# APM32F070 register map
File version: 1.0
Registers are 32-bit, read-write, reset 0x0 unless marked. A register's access mark holds for its fields unless they carry their own. Offsets are from the block's base; [hi:lo] are bit positions; {n}, {i} and the like mark numbered series.

## SYSCFG — System configuration controller
Base 0x40010000
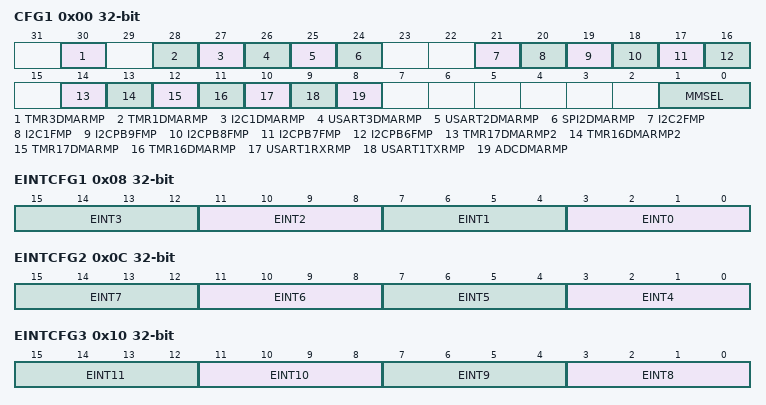
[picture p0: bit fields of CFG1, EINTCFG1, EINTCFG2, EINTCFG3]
0x00 CFG1 — configuration register 1
  [30] TMR3DMARMP — TMR3 DMA request remapping bit
  [28] TMR1DMARMP — TMR1 DMA request remapping bit
  [27] I2C1DMARMP — I2C1 DMA request remapping bit
  [26] USART3DMARMP — USART3 DMA request remapping bit
  [25] USART2DMARMP — USART2 DMA request remapping bit
  [24] SPI2DMARMP — SPI2 DMA request remapping bit.
  [21] I2C2FMP — FM+ driving capability activation for I2C1
  [20] I2C1FMP — FM+ driving capability activation for I2C1
  [19] I2CPB9FMP — Fast Mode Plus (FM+) driving capability activation bits.
  [18] I2CPB8FMP — Fast Mode Plus (FM+) driving capability activation bits.
  [17] I2CPB7FMP — Fast Mode Plus (FM+) driving capability activation bits.
  [16] I2CPB6FMP — Fast Mode Plus (FM plus) driving capability activation bits.
  [14] TMR17DMARMP2 — TMR17 alternate DMA request remapping bit.
  [13] TMR16DMARMP2 — TMR16 alternate DMA request remapping bit.
  [12] TMR17DMARMP — TMR17 DMA request remapping bit
  [11] TMR16DMARMP — TMR16 DMA request remapping bit
  [10] USART1RXRMP — USART1_RX DMA request remapping bit
  [9] USART1TXRMP — USART1_TX DMA remapping bit
  [8] ADCDMARMP — ADC DMA remapping bit
  [1:0] MMSEL — Memory mapping selection bits
0x08 EINTCFG1 — external interrupt configuration register 1
  [4n+3:4n] EINT{n} (n=0..3) — EINT {n} configuration bits
0x0C EINTCFG2 — external interrupt configuration register 2
  [4n-13:4n-16] EINT{n} (n=4..7) — EINT {n} configuration bits
0x10 EINTCFG3 — external interrupt configuration register 3
  [4n-29:4n-32] EINT{n} (n=8..11) — EINT {n} configuration bits
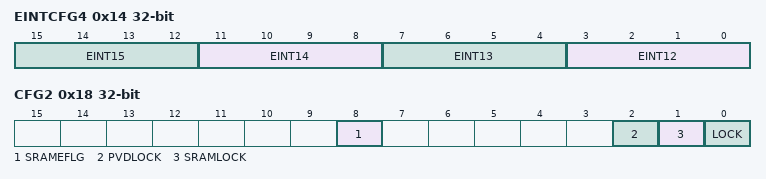
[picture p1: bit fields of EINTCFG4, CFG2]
0x14 EINTCFG4 — external interrupt configuration register 4
  [4n-45:4n-48] EINT{n} (n=12..15) — EINT {n} configuration bits
0x18 CFG2 — configuration register 2
  [8] SRAMEFLG — SRAM parity error flag
  [2] PVDLOCK — PVD lock enable bit
  [1] SRAMLOCK — SRAM parity lock bit
  [0] LOCK — Cortex-M0 Hardfault enable bit

## ADC — Analog-to-digital converter
Base 0x40012400
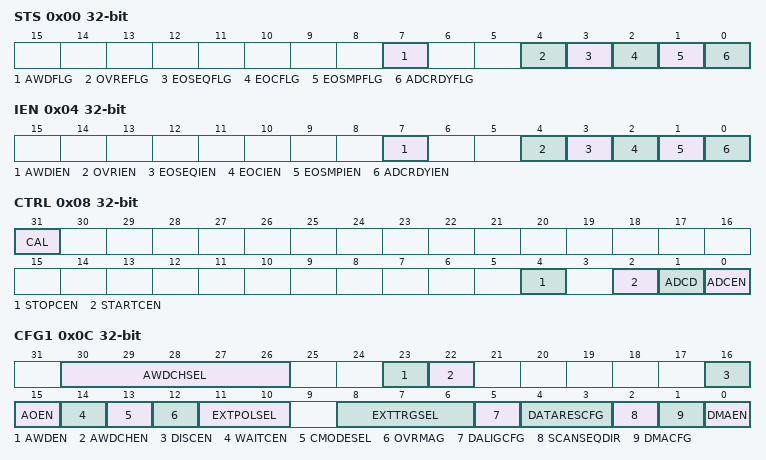
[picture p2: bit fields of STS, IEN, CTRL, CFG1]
0x00 STS — interrupt and status register
  [7] AWDFLG — Analog watchdog flag
  [4] OVREFLG — ADC overrun flag
  [3] EOSEQFLG — End of sequence flag
  [2] EOCFLG — End of conversion flag
  [1] EOSMPFLG — End of sampling flag
  [0] ADCRDYFLG — ADC ready flag
0x04 IEN — interrupt enable register
  [7] AWDIEN — Analog watchdog interrupt enable
  [4] OVRIEN — Overrun interrupt enable
  [3] EOSEQIEN — End of conversion sequence interrupt enable
  [2] EOCIEN — End of conversion interrupt enable
  [1] EOSMPIEN — End of sampling flag interrupt enable
  [0] ADCRDYIEN — ADC ready interrupt enable
0x08 CTRL — control register
  [31] CAL — ADC calibration
  [4] STOPCEN — ADC stop conversion command
  [2] STARTCEN — ADC start conversion command
  [1] ADCD — ADC disable command
  [0] ADCEN — ADC enable command
0x0C CFG1 — configuration register 1
  [30:26] AWDCHSEL — Analog watchdog channel selection
  [23] AWDEN — Analog watchdog enable
  [22] AWDCHEN — Enable the watchdog on a single channel or on all channels
  [16] DISCEN — Discontinuous mode
  [15] AOEN — Auto-off mode
  [14] WAITCEN — Auto-delayed conversion mode
  [13] CMODESEL — Single / continuous conversion mode
  [12] OVRMAG — Overrun management mode
  [11:10] EXTPOLSEL — External trigger enable and polarity selection
  [8:6] EXTTRGSEL — External trigger selection
  [5] DALIGCFG — Data alignment
  [4:3] DATARESCFG — Data resolution
  [2] SCANSEQDIR — Scan sequence direction
  [1] DMACFG — Direct memery access configuration
  [0] DMAEN — Direct memory access enable
0x10 CFG2 — configuration register 2
  [31:30] CLKCFG — ADC clock mode
0x14 SMPTIM — sampling time register
  [2:0] SMPCYCSEL — Sampling time selection
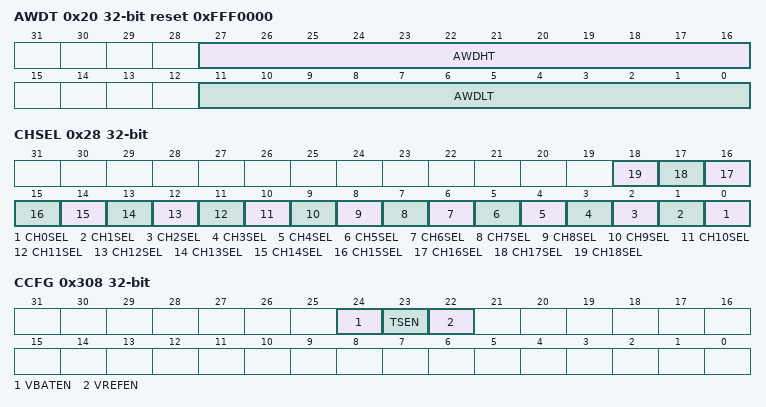
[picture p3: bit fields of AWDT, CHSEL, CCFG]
0x20 AWDT reset 0xFFF0000 — watchdog threshold register
  [27:16] AWDHT — Analog watchdog higher threshold
  [11:0] AWDLT — Analog watchdog lower threshold
0x28 CHSEL — channel selection register
  [n] CH{n}SEL (n=0..18) — Channel-{n} selection
0x40 DATA ro
  [15:0] CDATA — Converted data
0x308 CCFG — common configuration register
  [24] VBATEN — VBAT enable
  [23] TSEN — Temperature sensor enable
  [22] VREFEN — Temperature sensor and VREFINT enable
